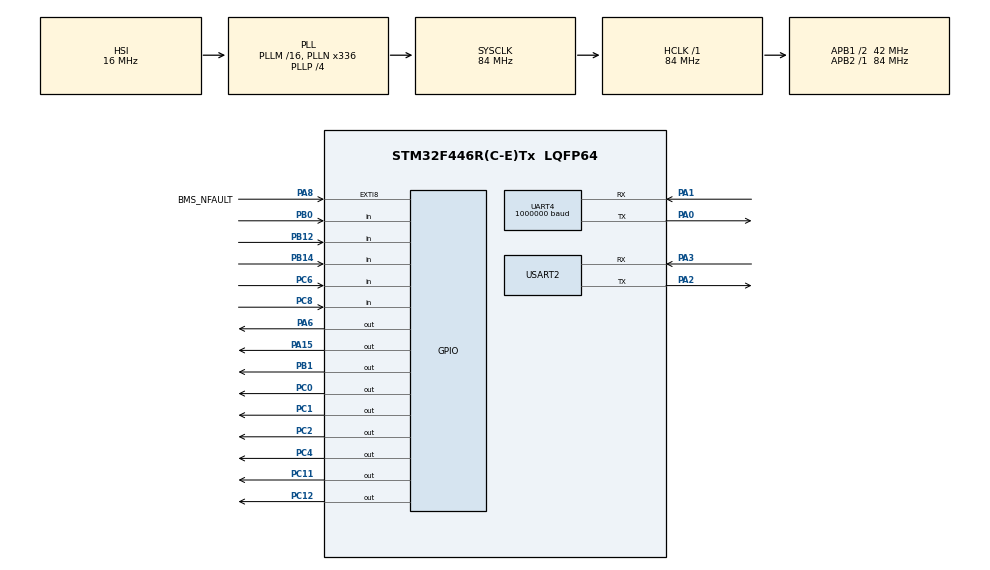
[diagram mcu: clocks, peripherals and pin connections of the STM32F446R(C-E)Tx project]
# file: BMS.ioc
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Dma.Request0=UART4_RX
Dma.Request1=UART4_TX
Dma.UART4_RX.0.Direction=DMA_PERIPH_TO_MEMORY
Dma.UART4_RX.0.FIFOMode=DMA_FIFOMODE_DISABLE
Dma.UART4_RX.0.Instance=DMA1_Stream2
Dma.UART4_RX.0.MemDataAlignment=DMA_MDATAALIGN_BYTE
Dma.UART4_RX.0.MemInc=DMA_MINC_ENABLE
Dma.UART4_RX.0.Mode=DMA_NORMAL
Dma.UART4_RX.0.PeriphDataAlignment=DMA_PDATAALIGN_BYTE
Dma.UART4_RX.0.PeriphInc=DMA_PINC_DISABLE
Dma.UART4_RX.0.Priority=DMA_PRIORITY_LOW
Dma.UART4_TX.1.Direction=DMA_MEMORY_TO_PERIPH
Dma.UART4_TX.1.FIFOMode=DMA_FIFOMODE_DISABLE
Dma.UART4_TX.1.Instance=DMA1_Stream4
Dma.UART4_TX.1.MemDataAlignment=DMA_MDATAALIGN_BYTE
Dma.UART4_TX.1.MemInc=DMA_MINC_ENABLE
Dma.UART4_TX.1.Mode=DMA_NORMAL
Dma.UART4_TX.1.PeriphDataAlignment=DMA_PDATAALIGN_BYTE
Dma.UART4_TX.1.PeriphInc=DMA_PINC_DISABLE
Dma.UART4_TX.1.Priority=DMA_PRIORITY_LOW
IWDG.Prescaler=IWDG_PRESCALER_64
IWDG.Reload=250
Mcu.Family=STM32F4
Mcu.Name=STM32F446R(C-E)Tx
Mcu.Package=LQFP64
NVIC.DMA1_Stream2_IRQn=true\:0\:0\:false\:false\:true\:false\:true\:true
NVIC.DMA1_Stream4_IRQn=true\:0\:0\:false\:false\:true\:false\:true\:true
NVIC.EXTI9_5_IRQn=true\:0\:0\:false\:false\:true\:true\:true\:true
NVIC.PriorityGroup=NVIC_PRIORITYGROUP_4
NVIC.TIM6_DAC_IRQn=true\:15\:0\:false\:false\:true\:false\:true\:true
NVIC.TimeBase=TIM6_DAC_IRQn
NVIC.TimeBaseIP=TIM6
NVIC.UART4_IRQn=true\:0\:0\:false\:false\:true\:true\:true\:true
PA0-WKUP.Mode=Asynchronous
PA0-WKUP.Signal=UART4_TX
PA1.Mode=Asynchronous
PA1.Signal=UART4_RX
PA13.Mode=Trace_Asynchronous_SW
PA13.Signal=SYS_JTMS-SWDIO
PA14.Mode=Trace_Asynchronous_SW
PA14.Signal=SYS_JTCK-SWCLK
PA15.Signal=GPIO_Output
PA2.Mode=Asynchronous
PA2.Signal=USART2_TX
PA3.Mode=Asynchronous
PA3.Signal=USART2_RX
PA6.Signal=GPIO_Output
PA8.GPIO_Label=BMS_NFAULT
PA8.GPIO_ModeDefaultEXTI=GPIO_MODE_IT_FALLING
PA8.GPIO_PuPd=GPIO_PULLUP
PA8.Signal=GPXTI8
PB0.GPIO_PuPd=GPIO_PULLDOWN
PB0.Signal=GPIO_Input
PB1.GPIO_ModeDefaultOutputPP=GPIO_MODE_OUTPUT_PP
PB1.GPIO_PuPd=GPIO_NOPULL
PB1.Signal=GPIO_Output
PB12.GPIO_PuPd=GPIO_PULLDOWN
PB12.Signal=GPIO_Input
PB14.GPIO_PuPd=GPIO_PULLDOWN
PB14.Signal=GPIO_Input
PB3.Mode=Trace_Asynchronous_SW
PB3.Signal=SYS_JTDO-SWO
PC0.Signal=GPIO_Output
PC1.Signal=GPIO_Output
PC11.Signal=GPIO_Output
PC12.Signal=GPIO_Output
PC2.Signal=GPIO_Output
PC4.Signal=GPIO_Output
PC6.GPIO_PuPd=GPIO_PULLDOWN
PC6.Signal=GPIO_Input
PC8.GPIO_PuPd=GPIO_PULLDOWN
PC8.Signal=GPIO_Input
ProjectManager.HeapSize=0x200
ProjectManager.StackSize=0x400
ProjectManager.TargetToolchain=STM32CubeIDE
RCC.AHBFreq_Value=84000000
RCC.APB1CLKDivider=RCC_HCLK_DIV2
RCC.APB1Freq_Value=42000000
RCC.APB1TimFreq_Value=84000000
RCC.APB2Freq_Value=84000000
RCC.APB2TimFreq_Value=84000000
RCC.CortexFreq_Value=84000000
RCC.HCLKFreq_Value=84000000
RCC.PLLN=336
RCC.PLLP=RCC_PLLP_DIV4
RCC.SYSCLKFreq_VALUE=84000000
RCC.SYSCLKSource=RCC_SYSCLKSOURCE_PLLCLK
RCC.USBFreq_Value=168000000
RCC.VCOOutputFreq_Value=336000000
TIM2.Prescaler=83
UART4.BaudRate=1000000
UART4.VirtualMode=Asynchronous
USART2.VirtualMode=VM_ASYNC
VP_IWDG_VS_IWDG.Mode=IWDG_Activate
VP_SYS_VS_tim6.Mode=TIM6
VP_TIM2_VS_ClockSourceINT.Mode=Internal
board=custom

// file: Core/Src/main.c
/* USER CODE BEGIN Header */
/**
  ******************************************************************************
  * @file           : main.c
  * @brief          : Main program body
  ******************************************************************************
  * @attention
  *
  * Copyright (c) 2026 STMicroelectronics.
  * All rights reserved.
  *
  * This software is licensed under terms that can be found in the LICENSE file
  * in the root directory of this software component.
  * If no LICENSE file comes with this software, it is provided AS-IS.
  *
  ******************************************************************************
  */
/* USER CODE END Header */
#include "main.h"

/* USER CODE BEGIN Includes */
#include "bq796xx_bms.h"
/* USER CODE END Includes */

IWDG_HandleTypeDef hiwdg;

TIM_HandleTypeDef htim2;

UART_HandleTypeDef huart4;
UART_HandleTypeDef huart2;
DMA_HandleTypeDef hdma_uart4_rx;
DMA_HandleTypeDef hdma_uart4_tx;

void SystemClock_Config(void);
static void MX_GPIO_Init(void);
static void MX_DMA_Init(void);
static void MX_TIM2_Init(void);
static void MX_UART4_Init(void);
static void MX_USART2_UART_Init(void);
static void MX_IWDG_Init(void);
/* USER CODE BEGIN PFP */

void BMS_Main(void);

/* USER CODE END PFP */

/* USER CODE BEGIN 0 */

/* Redireciona o printf para o USART2 (PA2) — debug/telemetria.
   * __io_putchar é declarado 'weak' em syscalls.c; esta definição forte
   * sobrepõe-se e encaminha cada caráter para a UART de debug. */
  int __io_putchar(int ch)
  {
    uint8_t c = (uint8_t)ch;
    HAL_UART_Transmit(&huart2, &c, 1U, 10U);
    return ch;
  }

/* USER CODE END 0 */

int main(void)
{

  /* MCU Configuration--------------------------------------------------------*/

  /* Reset of all peripherals, Initializes the Flash interface and the Systick. */
  HAL_Init();

  /* Configure the system clock */
  SystemClock_Config();

  /* Initialize all configured peripherals */
  MX_GPIO_Init();
  MX_DMA_Init();
  MX_TIM2_Init();
  MX_UART4_Init();
  MX_USART2_UART_Init();
  MX_IWDG_Init();
  /* USER CODE BEGIN 2 */

  BMS_Main();

  /* USER CODE END 2 */

  /* Infinite loop */
  while (1)
  {

  }
}

void SystemClock_Config(void)
{
  RCC_OscInitTypeDef RCC_OscInitStruct = {0};
  RCC_ClkInitTypeDef RCC_ClkInitStruct = {0};

  /** Configure the main internal regulator output voltage
  */
  __HAL_RCC_PWR_CLK_ENABLE();
  __HAL_PWR_VOLTAGESCALING_CONFIG(PWR_REGULATOR_VOLTAGE_SCALE3);

  /** Initializes the RCC Oscillators according to the specified parameters
  * in the RCC_OscInitTypeDef structure.
  */
  RCC_OscInitStruct.OscillatorType = RCC_OSCILLATORTYPE_HSI|RCC_OSCILLATORTYPE_LSI;
  RCC_OscInitStruct.HSIState = RCC_HSI_ON;
  RCC_OscInitStruct.HSICalibrationValue = RCC_HSICALIBRATION_DEFAULT;
  RCC_OscInitStruct.LSIState = RCC_LSI_ON;
  RCC_OscInitStruct.PLL.PLLState = RCC_PLL_ON;
  RCC_OscInitStruct.PLL.PLLSource = RCC_PLLSOURCE_HSI;
  RCC_OscInitStruct.PLL.PLLM = 16;
  RCC_OscInitStruct.PLL.PLLN = 336;
  RCC_OscInitStruct.PLL.PLLP = RCC_PLLP_DIV4;
  RCC_OscInitStruct.PLL.PLLQ = 2;
  RCC_OscInitStruct.PLL.PLLR = 2;
  if (HAL_RCC_OscConfig(&RCC_OscInitStruct) != HAL_OK)
  {
    Error_Handler();
  }

  /** Initializes the CPU, AHB and APB buses clocks
  */
  RCC_ClkInitStruct.ClockType = RCC_CLOCKTYPE_HCLK|RCC_CLOCKTYPE_SYSCLK
                              |RCC_CLOCKTYPE_PCLK1|RCC_CLOCKTYPE_PCLK2;
  RCC_ClkInitStruct.SYSCLKSource = RCC_SYSCLKSOURCE_PLLCLK;
  RCC_ClkInitStruct.AHBCLKDivider = RCC_SYSCLK_DIV1;
  RCC_ClkInitStruct.APB1CLKDivider = RCC_HCLK_DIV2;
  RCC_ClkInitStruct.APB2CLKDivider = RCC_HCLK_DIV1;

  if (HAL_RCC_ClockConfig(&RCC_ClkInitStruct, FLASH_LATENCY_2) != HAL_OK)
  {
    Error_Handler();
  }
}

static void MX_IWDG_Init(void)
{

  hiwdg.Instance = IWDG;
  hiwdg.Init.Prescaler = IWDG_PRESCALER_64;
  hiwdg.Init.Reload = 250;
  if (HAL_IWDG_Init(&hiwdg) != HAL_OK)
  {
    Error_Handler();
  }

}

static void MX_TIM2_Init(void)
{

  TIM_ClockConfigTypeDef sClockSourceConfig = {0};
  TIM_MasterConfigTypeDef sMasterConfig = {0};

  htim2.Instance = TIM2;
  htim2.Init.Prescaler = 83;
  htim2.Init.CounterMode = TIM_COUNTERMODE_UP;
  htim2.Init.Period = 4294967295;
  htim2.Init.ClockDivision = TIM_CLOCKDIVISION_DIV1;
  htim2.Init.AutoReloadPreload = TIM_AUTORELOAD_PRELOAD_DISABLE;
  if (HAL_TIM_Base_Init(&htim2) != HAL_OK)
  {
    Error_Handler();
  }
  sClockSourceConfig.ClockSource = TIM_CLOCKSOURCE_INTERNAL;
  if (HAL_TIM_ConfigClockSource(&htim2, &sClockSourceConfig) != HAL_OK)
  {
    Error_Handler();
  }
  sMasterConfig.MasterOutputTrigger = TIM_TRGO_RESET;
  sMasterConfig.MasterSlaveMode = TIM_MASTERSLAVEMODE_DISABLE;
  if (HAL_TIMEx_MasterConfigSynchronization(&htim2, &sMasterConfig) != HAL_OK)
  {
    Error_Handler();
  }

}

static void MX_UART4_Init(void)
{

  huart4.Instance = UART4;
  huart4.Init.BaudRate = 1000000;
  huart4.Init.WordLength = UART_WORDLENGTH_8B;
  huart4.Init.StopBits = UART_STOPBITS_1;
  huart4.Init.Parity = UART_PARITY_NONE;
  huart4.Init.Mode = UART_MODE_TX_RX;
  huart4.Init.HwFlowCtl = UART_HWCONTROL_NONE;
  huart4.Init.OverSampling = UART_OVERSAMPLING_16;
  if (HAL_UART_Init(&huart4) != HAL_OK)
  {
    Error_Handler();
  }

}

static void MX_USART2_UART_Init(void)
{

  huart2.Instance = USART2;
  huart2.Init.BaudRate = 115200;
  huart2.Init.WordLength = UART_WORDLENGTH_8B;
  huart2.Init.StopBits = UART_STOPBITS_1;
  huart2.Init.Parity = UART_PARITY_NONE;
  huart2.Init.Mode = UART_MODE_TX_RX;
  huart2.Init.HwFlowCtl = UART_HWCONTROL_NONE;
  huart2.Init.OverSampling = UART_OVERSAMPLING_16;
  if (HAL_UART_Init(&huart2) != HAL_OK)
  {
    Error_Handler();
  }

}

static void MX_DMA_Init(void)
{

  /* DMA controller clock enable */
  __HAL_RCC_DMA1_CLK_ENABLE();

  /* DMA interrupt init */
  /* DMA1_Stream2_IRQn interrupt configuration */
  HAL_NVIC_SetPriority(DMA1_Stream2_IRQn, 0, 0);
  HAL_NVIC_EnableIRQ(DMA1_Stream2_IRQn);
  /* DMA1_Stream4_IRQn interrupt configuration */
  HAL_NVIC_SetPriority(DMA1_Stream4_IRQn, 0, 0);
  HAL_NVIC_EnableIRQ(DMA1_Stream4_IRQn);

}

static void MX_GPIO_Init(void)
{
  GPIO_InitTypeDef GPIO_InitStruct = {0};

  /* GPIO Ports Clock Enable */
  __HAL_RCC_GPIOC_CLK_ENABLE();
  __HAL_RCC_GPIOA_CLK_ENABLE();
  __HAL_RCC_GPIOB_CLK_ENABLE();

  /*Configure GPIO pin Output Level */
  HAL_GPIO_WritePin(GPIOC, GPIO_PIN_0|GPIO_PIN_1|GPIO_PIN_2|GPIO_PIN_4
                          |GPIO_PIN_11|GPIO_PIN_12, GPIO_PIN_RESET);

  /*Configure GPIO pin Output Level */
  HAL_GPIO_WritePin(GPIOA, GPIO_PIN_6|GPIO_PIN_15, GPIO_PIN_RESET);

  /*Configure GPIO pin Output Level */
  HAL_GPIO_WritePin(GPIOB, GPIO_PIN_1, GPIO_PIN_RESET);

  /*Configure GPIO pins : PC0 PC1 PC2 PC4
                           PC11 PC12 */
  GPIO_InitStruct.Pin = GPIO_PIN_0|GPIO_PIN_1|GPIO_PIN_2|GPIO_PIN_4
                          |GPIO_PIN_11|GPIO_PIN_12;
  GPIO_InitStruct.Mode = GPIO_MODE_OUTPUT_PP;
  GPIO_InitStruct.Pull = GPIO_NOPULL;
  GPIO_InitStruct.Speed = GPIO_SPEED_FREQ_LOW;
  HAL_GPIO_Init(GPIOC, &GPIO_InitStruct);

  /*Configure GPIO pins : PA6 PA15 */
  GPIO_InitStruct.Pin = GPIO_PIN_6|GPIO_PIN_15;
  GPIO_InitStruct.Mode = GPIO_MODE_OUTPUT_PP;
  GPIO_InitStruct.Pull = GPIO_NOPULL;
  GPIO_InitStruct.Speed = GPIO_SPEED_FREQ_LOW;
  HAL_GPIO_Init(GPIOA, &GPIO_InitStruct);

  /*Configure GPIO pins : PB0 PB12 PB14 */
  GPIO_InitStruct.Pin = GPIO_PIN_0|GPIO_PIN_12|GPIO_PIN_14;
  GPIO_InitStruct.Mode = GPIO_MODE_INPUT;
  GPIO_InitStruct.Pull = GPIO_PULLDOWN;
  HAL_GPIO_Init(GPIOB, &GPIO_InitStruct);

  /*Configure GPIO pin : PB1 */
  GPIO_InitStruct.Pin = GPIO_PIN_1;
  GPIO_InitStruct.Mode = GPIO_MODE_OUTPUT_PP;
  GPIO_InitStruct.Pull = GPIO_NOPULL;
  GPIO_InitStruct.Speed = GPIO_SPEED_FREQ_LOW;
  HAL_GPIO_Init(GPIOB, &GPIO_InitStruct);

  /*Configure GPIO pins : PC6 PC8 */
  GPIO_InitStruct.Pin = GPIO_PIN_6|GPIO_PIN_8;
  GPIO_InitStruct.Mode = GPIO_MODE_INPUT;
  GPIO_InitStruct.Pull = GPIO_PULLDOWN;
  HAL_GPIO_Init(GPIOC, &GPIO_InitStruct);

  /*Configure GPIO pin : BMS_NFAULT_Pin */
  GPIO_InitStruct.Pin = BMS_NFAULT_Pin;
  GPIO_InitStruct.Mode = GPIO_MODE_IT_FALLING;
  GPIO_InitStruct.Pull = GPIO_PULLUP;
  HAL_GPIO_Init(BMS_NFAULT_GPIO_Port, &GPIO_InitStruct);

  /* EXTI interrupt init*/
  HAL_NVIC_SetPriority(EXTI9_5_IRQn, 0, 0);
  HAL_NVIC_EnableIRQ(EXTI9_5_IRQn);

}

void HAL_TIM_PeriodElapsedCallback(TIM_HandleTypeDef *htim)
{
  if (htim->Instance == TIM6)
  {
    HAL_IncTick();
  }
}

void Error_Handler(void)
{
  __disable_irq();
  while (1)
  {
  }
}
